# MKW38A4 register map
Vendor: NXP Semiconductors; Series: Kinetis_W; File version: 1.6
CPU: CM0PLUS r0p0, little endian, no MPU, no FPU, VTOR, 2 interrupt priority bits
Registers are 32-bit, read-write, no defined reset value unless marked. A register's access mark holds for its fields unless they carry their own. Offsets are from the block's base; [hi:lo] are bit positions; {n}, {i} and the like mark numbered series.

## NVIC — Nested Vectored Interrupt Controller
Base 0xE000E100
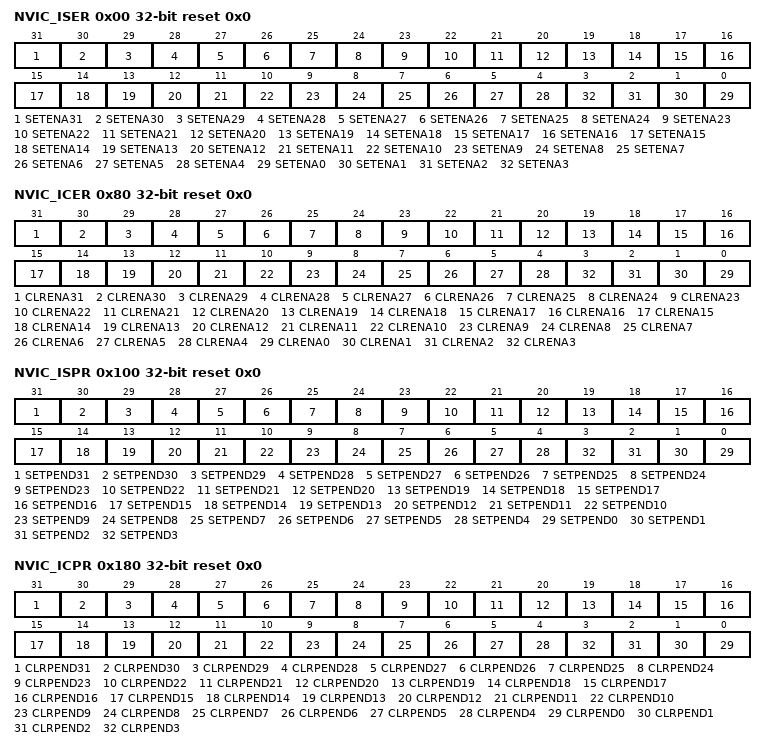
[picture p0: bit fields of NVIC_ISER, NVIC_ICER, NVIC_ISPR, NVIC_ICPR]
0x00 NVIC_ISER reset 0x0 — Interrupt Set Enable Register
  [31] SETENA31 — Pin detect Port B and C interrupt set-enable bit
    0=write: no effect; read: Pin detect Port B and C interrupt disabled; 1=write: enable Pin detect Port B and C interrupt; read: Pin detect Port B and C interrupt enabled
  [30] SETENA30 — Pin detect Port A interrupt set-enable bit
    0=write: no effect; read: Pin detect Port A interrupt disabled; 1=write: enable Pin detect Port A interrupt; read: Pin detect Port A interrupt enabled
  [29] SETENA29 — Serial Peripheral Interface 1 interrupt set-enable bit
    0=write: no effect; read: Serial Peripheral Interface 1 interrupt disabled; 1=write: enable Serial Peripheral Interface 1 interrupt; read: Serial Peripheral Interface 1 interrupt enabled
  [28] SETENA28 — Low-Power Timer 0 interrupt set-enable bit
    0=write: no effect; read: Low-Power Timer 0 interrupt disabled; 1=write: enable Low-Power Timer 0 interrupt; read: Low-Power Timer 0 interrupt enabled
  [27] SETENA27 — Multipurpose Clock Generator interrupt set-enable bit
    0=write: no effect; read: Multipurpose Clock Generator interrupt disabled; 1=write: enable Multipurpose Clock Generator interrupt; read: Multipurpose Clock Generator interrupt enabled
  [26] SETENA26 — Radio 1 interrupt set-enable bit
    0=write: no effect; read: Radio 1 interrupt disabled; 1=write: enable Radio 1 interrupt; read: Radio 1 interrupt enabled
  [25] SETENA25 — FlexCAN0 ORed Message Buffer (MB0-31) interrupt interrupt set-enable bit
    0=write: no effect; read: FlexCAN0 ORed Message Buffer (MB0-31) interrupt interrupt disabled; 1=write: enable FlexCAN0 ORed Message Buffer (MB0-31) interrupt interrupt; read: FlexCAN0 ORed Message Buffer (MB0-31) interrupt interrupt enabled
  [24] SETENA24 — Radio 0 interrupt set-enable bit
    0=write: no effect; read: Radio 0 interrupt disabled; 1=write: enable Radio 0 interrupt; read: Radio 0 interrupt enabled
  [23] SETENA23 — LTC0 interrupt set-enable bit
    0=write: no effect; read: LTC0 interrupt disabled; 1=write: enable LTC0 interrupt; read: LTC0 interrupt enabled
  [22] SETENA22 — Periodic Interrupt Timer interrupt set-enable bit
    0=write: no effect; read: Periodic Interrupt Timer interrupt disabled; 1=write: enable Periodic Interrupt Timer interrupt; read: Periodic Interrupt Timer interrupt enabled
  [21] SETENA21 — RTC seconds interrupt set-enable bit
    0=write: no effect; read: RTC seconds interrupt disabled; 1=write: enable RTC seconds interrupt; read: RTC seconds interrupt enabled
  [20] SETENA20 — Real-time counter interrupt set-enable bit
    0=write: no effect; read: Real-time counter interrupt disabled; 1=write: enable Real-time counter interrupt; read: Real-time counter interrupt enabled
  [19] SETENA19 — Timer/PWM module 2 interrupt set-enable bit
    0=write: no effect; read: Timer/PWM module 2 interrupt disabled; 1=write: enable Timer/PWM module 2 interrupt; read: Timer/PWM module 2 interrupt enabled
  [18] SETENA18 — Timer/PWM module 1 interrupt set-enable bit
    0=write: no effect; read: Timer/PWM module 1 interrupt disabled; 1=write: enable Timer/PWM module 1 interrupt; read: Timer/PWM module 1 interrupt enabled
  [17] SETENA17 — Timer/PWM module 0 interrupt set-enable bit
    0=write: no effect; read: Timer/PWM module 0 interrupt disabled; 1=write: enable Timer/PWM module 0 interrupt; read: Timer/PWM module 0 interrupt enabled
  [16] SETENA16 — DMA channel 0 - 31 error interrupt set-enable bit
    0=write: no effect; read: DMA channel 0 - 31 error interrupt disabled; 1=write: enable DMA channel 0 - 31 error interrupt; read: DMA channel 0 - 31 error interrupt enabled
  [15] SETENA15 — Analog-to-Digital Converter 0 interrupt set-enable bit
    0=write: no effect; read: Analog-to-Digital Converter 0 interrupt disabled; 1=write: enable Analog-to-Digital Converter 0 interrupt; read: Analog-to-Digital Converter 0 interrupt enabled
  [14] SETENA14 — Carrier modulator transmitter interrupt set-enable bit
    0=write: no effect; read: Carrier modulator transmitter interrupt disabled; 1=write: enable Carrier modulator transmitter interrupt; read: Carrier modulator transmitter interrupt enabled
  [13] SETENA13 — True Random Number Generator interrupt set-enable bit
    0=write: no effect; read: True Random Number Generator interrupt disabled; 1=write: enable True Random Number Generator interrupt; read: True Random Number Generator interrupt enabled
  [12] SETENA12 — LPUART0 or LPUART1 status and error interrupt set-enable bit
    0=write: no effect; read: LPUART0 or LPUART1 status and error interrupt disabled; 1=write: enable LPUART0 or LPUART1 status and error interrupt; read: LPUART0 or LPUART1 status and error interrupt enabled
  [11] SETENA11 — FlexCAN0 ORed Error, Bus off, Transmit/Receive Warning, Wake up interrupt set-enable bit
    0=write: no effect; read: FlexCAN0 ORed Error, Bus off, Transmit/Receive Warning, Wake up interrupt disabled; 1=write: enable FlexCAN0 ORed Error, Bus off, Transmit/Receive Warning, Wake up interrupt; read: FlexCAN0 ORed Error, Bus off, Transmit/Receive Warning, Wake up interrupt enabled
  [10] SETENA10 — Serial Peripheral Interface 0 interrupt set-enable bit
    0=write: no effect; read: Serial Peripheral Interface 0 interrupt disabled; 1=write: enable Serial Peripheral Interface 0 interrupt; read: Serial Peripheral Interface 0 interrupt enabled
  [9] SETENA9 — Inter-Integrated Circuit 1 interrupt set-enable bit
    0=write: no effect; read: Inter-Integrated Circuit 1 interrupt disabled; 1=write: enable Inter-Integrated Circuit 1 interrupt; read: Inter-Integrated Circuit 1 interrupt enabled
  [8] SETENA8 — Inter-Integrated Circuit 0 interrupt set-enable bit
    0=write: no effect; read: Inter-Integrated Circuit 0 interrupt disabled; 1=write: enable Inter-Integrated Circuit 0 interrupt; read: Inter-Integrated Circuit 0 interrupt enabled
  [7] SETENA7 — Low Leakage Wakeup interrupt set-enable bit
    0=write: no effect; read: Low Leakage Wakeup interrupt disabled; 1=write: enable Low Leakage Wakeup interrupt; read: Low Leakage Wakeup interrupt enabled
  [6] SETENA6 — Low-voltage detect, low-voltage warning and DCDC PSWITCH interrupt interrupt set-enable bit
    0=write: no effect; read: Low-voltage detect, low-voltage warning and DCDC PSWITCH interrupt interrupt disabled; 1=write: enable Low-voltage detect, low-voltage warning and DCDC PSWITCH interrupt interrupt; read: Low-voltage detect, low-voltage warning and DCDC PSWITCH interrupt interrupt enabled
  [5] SETENA5 — Command complete and read collision, Flash ECC Errors interrupt set-enable bit
    0=write: no effect; read: Command complete and read collision, Flash ECC Errors interrupt disabled; 1=write: enable Command complete and read collision, Flash ECC Errors interrupt; read: Command complete and read collision, Flash ECC Errors interrupt enabled
  [4] SETENA4 — FIFO underrun, FIFO overflow, data ready, transfer complete and error interrupt set-enable bit
    0=write: no effect; read: FIFO underrun, FIFO overflow, data ready, transfer complete and error interrupt disabled; 1=write: enable FIFO underrun, FIFO overflow, data ready, transfer complete and error interrupt; read: FIFO underrun, FIFO overflow, data ready, transfer complete and error interrupt enabled
  [n] SETENA{n} (n=0..3) — DMA channel {n} transfer complete/error interrupt set-enable bit
    0=write: no effect; read: DMA channel {n} transfer complete/error interrupt disabled; 1=write: enable DMA channel {n} transfer complete/error interrupt; read: DMA channel {n} transfer complete/error interrupt enabled
0x80 NVIC_ICER reset 0x0 — Interrupt Clear Enable Register
  [31] CLRENA31 — Pin detect Port B and C interrupt clear-enable bit
    0=write: no effect; read: Pin detect Port B and C interrupt disabled; 1=write: disable Pin detect Port B and C interrupt; read: Pin detect Port B and C interrupt enabled
  [30] CLRENA30 — Pin detect Port A interrupt clear-enable bit
    0=write: no effect; read: Pin detect Port A interrupt disabled; 1=write: disable Pin detect Port A interrupt; read: Pin detect Port A interrupt enabled
  [29] CLRENA29 — Serial Peripheral Interface 1 interrupt clear-enable bit
    0=write: no effect; read: Serial Peripheral Interface 1 interrupt disabled; 1=write: disable Serial Peripheral Interface 1 interrupt; read: Serial Peripheral Interface 1 interrupt enabled
  [28] CLRENA28 — Low-Power Timer 0 interrupt clear-enable bit
    0=write: no effect; read: Low-Power Timer 0 interrupt disabled; 1=write: disable Low-Power Timer 0 interrupt; read: Low-Power Timer 0 interrupt enabled
  [27] CLRENA27 — Multipurpose Clock Generator interrupt clear-enable bit
    0=write: no effect; read: Multipurpose Clock Generator interrupt disabled; 1=write: disable Multipurpose Clock Generator interrupt; read: Multipurpose Clock Generator interrupt enabled
  [26] CLRENA26 — Radio 1 interrupt clear-enable bit
    0=write: no effect; read: Radio 1 interrupt disabled; 1=write: disable Radio 1 interrupt; read: Radio 1 interrupt enabled
  [25] CLRENA25 — FlexCAN0 ORed Message Buffer (MB0-31) interrupt interrupt clear-enable bit
    0=write: no effect; read: FlexCAN0 ORed Message Buffer (MB0-31) interrupt interrupt disabled; 1=write: disable FlexCAN0 ORed Message Buffer (MB0-31) interrupt interrupt; read: FlexCAN0 ORed Message Buffer (MB0-31) interrupt interrupt enabled
  [24] CLRENA24 — Radio 0 interrupt clear-enable bit
    0=write: no effect; read: Radio 0 interrupt disabled; 1=write: disable Radio 0 interrupt; read: Radio 0 interrupt enabled
  [23] CLRENA23 — LTC0 interrupt clear-enable bit
    0=write: no effect; read: LTC0 interrupt disabled; 1=write: disable LTC0 interrupt; read: LTC0 interrupt enabled
  [22] CLRENA22 — Periodic Interrupt Timer interrupt clear-enable bit
    0=write: no effect; read: Periodic Interrupt Timer interrupt disabled; 1=write: disable Periodic Interrupt Timer interrupt; read: Periodic Interrupt Timer interrupt enabled
  [21] CLRENA21 — RTC seconds interrupt clear-enable bit
    0=write: no effect; read: RTC seconds interrupt disabled; 1=write: disable RTC seconds interrupt; read: RTC seconds interrupt enabled
  [20] CLRENA20 — Real-time counter interrupt clear-enable bit
    0=write: no effect; read: Real-time counter interrupt disabled; 1=write: disable Real-time counter interrupt; read: Real-time counter interrupt enabled
  [19] CLRENA19 — Timer/PWM module 2 interrupt clear-enable bit
    0=write: no effect; read: Timer/PWM module 2 interrupt disabled; 1=write: disable Timer/PWM module 2 interrupt; read: Timer/PWM module 2 interrupt enabled
  [18] CLRENA18 — Timer/PWM module 1 interrupt clear-enable bit
    0=write: no effect; read: Timer/PWM module 1 interrupt disabled; 1=write: disable Timer/PWM module 1 interrupt; read: Timer/PWM module 1 interrupt enabled
  [17] CLRENA17 — Timer/PWM module 0 interrupt clear-enable bit
    0=write: no effect; read: Timer/PWM module 0 interrupt disabled; 1=write: disable Timer/PWM module 0 interrupt; read: Timer/PWM module 0 interrupt enabled
  [16] CLRENA16 — DMA channel 0 - 31 error interrupt clear-enable bit
    0=write: no effect; read: DMA channel 0 - 31 error interrupt disabled; 1=write: disable DMA channel 0 - 31 error interrupt; read: DMA channel 0 - 31 error interrupt enabled
  [15] CLRENA15 — Analog-to-Digital Converter 0 interrupt clear-enable bit
    0=write: no effect; read: Analog-to-Digital Converter 0 interrupt disabled; 1=write: disable Analog-to-Digital Converter 0 interrupt; read: Analog-to-Digital Converter 0 interrupt enabled
  [14] CLRENA14 — Carrier modulator transmitter interrupt clear-enable bit
    0=write: no effect; read: Carrier modulator transmitter interrupt disabled; 1=write: disable Carrier modulator transmitter interrupt; read: Carrier modulator transmitter interrupt enabled
  [13] CLRENA13 — True Random Number Generator interrupt clear-enable bit
    0=write: no effect; read: True Random Number Generator interrupt disabled; 1=write: disable True Random Number Generator interrupt; read: True Random Number Generator interrupt enabled
  [12] CLRENA12 — LPUART0 or LPUART1 status and error interrupt clear-enable bit
    0=write: no effect; read: LPUART0 or LPUART1 status and error interrupt disabled; 1=write: disable LPUART0 or LPUART1 status and error interrupt; read: LPUART0 or LPUART1 status and error interrupt enabled
  [11] CLRENA11 — FlexCAN0 ORed Error, Bus off, Transmit/Receive Warning, Wake up interrupt clear-enable bit
    0=write: no effect; read: FlexCAN0 ORed Error, Bus off, Transmit/Receive Warning, Wake up interrupt disabled; 1=write: disable FlexCAN0 ORed Error, Bus off, Transmit/Receive Warning, Wake up interrupt; read: FlexCAN0 ORed Error, Bus off, Transmit/Receive Warning, Wake up interrupt enabled
  [10] CLRENA10 — Serial Peripheral Interface 0 interrupt clear-enable bit
    0=write: no effect; read: Serial Peripheral Interface 0 interrupt disabled; 1=write: disable Serial Peripheral Interface 0 interrupt; read: Serial Peripheral Interface 0 interrupt enabled
  [9] CLRENA9 — Inter-Integrated Circuit 1 interrupt clear-enable bit
    0=write: no effect; read: Inter-Integrated Circuit 1 interrupt disabled; 1=write: disable Inter-Integrated Circuit 1 interrupt; read: Inter-Integrated Circuit 1 interrupt enabled
  [8] CLRENA8 — Inter-Integrated Circuit 0 interrupt clear-enable bit
    0=write: no effect; read: Inter-Integrated Circuit 0 interrupt disabled; 1=write: disable Inter-Integrated Circuit 0 interrupt; read: Inter-Integrated Circuit 0 interrupt enabled
  [7] CLRENA7 — Low Leakage Wakeup interrupt clear-enable bit
    0=write: no effect; read: Low Leakage Wakeup interrupt disabled; 1=write: disable Low Leakage Wakeup interrupt; read: Low Leakage Wakeup interrupt enabled
  [6] CLRENA6 — Low-voltage detect, low-voltage warning and DCDC PSWITCH interrupt interrupt clear-enable bit
    0=write: no effect; read: Low-voltage detect, low-voltage warning and DCDC PSWITCH interrupt interrupt disabled; 1=write: disable Low-voltage detect, low-voltage warning and DCDC PSWITCH interrupt interrupt; read: Low-voltage detect, low-voltage warning and DCDC PSWITCH interrupt interrupt enabled
  [5] CLRENA5 — Command complete and read collision, Flash ECC Errors interrupt clear-enable bit
    0=write: no effect; read: Command complete and read collision, Flash ECC Errors interrupt disabled; 1=write: disable Command complete and read collision, Flash ECC Errors interrupt; read: Command complete and read collision, Flash ECC Errors interrupt enabled
  [4] CLRENA4 — FIFO underrun, FIFO overflow, data ready, transfer complete and error interrupt clear-enable bit
    0=write: no effect; read: FIFO underrun, FIFO overflow, data ready, transfer complete and error interrupt disabled; 1=write: disable FIFO underrun, FIFO overflow, data ready, transfer complete and error interrupt; read: FIFO underrun, FIFO overflow, data ready, transfer complete and error interrupt enabled
  [n] CLRENA{n} (n=0..3) — DMA channel {n} transfer complete/error interrupt clear-enable bit
    0=write: no effect; read: DMA channel {n} transfer complete/error interrupt disabled; 1=write: disable DMA channel {n} transfer complete/error interrupt; read: DMA channel {n} transfer complete/error interrupt enabled
0x100 NVIC_ISPR reset 0x0 — Interrupt Set Pending Register
  [31] SETPEND31 — Pin detect Port B and C interrupt set-pending bit
    0=write: no effect; read: Pin detect Port B and C interrupt is not pending; 1=write: changes the Pin detect Port B and C interrupt state to pending; read: Pin detect Port B and C interrupt is pending
  [30] SETPEND30 — Pin detect Port A interrupt set-pending bit
    0=write: no effect; read: Pin detect Port A interrupt is not pending; 1=write: changes the Pin detect Port A interrupt state to pending; read: Pin detect Port A interrupt is pending
  [29] SETPEND29 — Serial Peripheral Interface 1 interrupt set-pending bit
    0=write: no effect; read: Serial Peripheral Interface 1 interrupt is not pending; 1=write: changes the Serial Peripheral Interface 1 interrupt state to pending; read: Serial Peripheral Interface 1 interrupt is pending
  [28] SETPEND28 — Low-Power Timer 0 interrupt set-pending bit
    0=write: no effect; read: Low-Power Timer 0 interrupt is not pending; 1=write: changes the Low-Power Timer 0 interrupt state to pending; read: Low-Power Timer 0 interrupt is pending
  [27] SETPEND27 — Multipurpose Clock Generator interrupt set-pending bit
    0=write: no effect; read: Multipurpose Clock Generator interrupt is not pending; 1=write: changes the Multipurpose Clock Generator interrupt state to pending; read: Multipurpose Clock Generator interrupt is pending
  [26] SETPEND26 — Radio 1 interrupt set-pending bit
    0=write: no effect; read: Radio 1 interrupt is not pending; 1=write: changes the Radio 1 interrupt state to pending; read: Radio 1 interrupt is pending
  [25] SETPEND25 — FlexCAN0 ORed Message Buffer (MB0-31) interrupt interrupt set-pending bit
    0=write: no effect; read: FlexCAN0 ORed Message Buffer (MB0-31) interrupt interrupt is not pending; 1=write: changes the FlexCAN0 ORed Message Buffer (MB0-31) interrupt interrupt state to pending; read: FlexCAN0 ORed Message Buffer (MB0-31) interrupt interrupt is pending
  [24] SETPEND24 — Radio 0 interrupt set-pending bit
    0=write: no effect; read: Radio 0 interrupt is not pending; 1=write: changes the Radio 0 interrupt state to pending; read: Radio 0 interrupt is pending
  [23] SETPEND23 — LTC0 interrupt set-pending bit
    0=write: no effect; read: LTC0 interrupt is not pending; 1=write: changes the LTC0 interrupt state to pending; read: LTC0 interrupt is pending
  [22] SETPEND22 — Periodic Interrupt Timer interrupt set-pending bit
    0=write: no effect; read: Periodic Interrupt Timer interrupt is not pending; 1=write: changes the Periodic Interrupt Timer interrupt state to pending; read: Periodic Interrupt Timer interrupt is pending
  [21] SETPEND21 — RTC seconds interrupt set-pending bit
    0=write: no effect; read: RTC seconds interrupt is not pending; 1=write: changes the RTC seconds interrupt state to pending; read: RTC seconds interrupt is pending
  [20] SETPEND20 — Real-time counter interrupt set-pending bit
    0=write: no effect; read: Real-time counter interrupt is not pending; 1=write: changes the Real-time counter interrupt state to pending; read: Real-time counter interrupt is pending
  [19] SETPEND19 — Timer/PWM module 2 interrupt set-pending bit
    0=write: no effect; read: Timer/PWM module 2 interrupt is not pending; 1=write: changes the Timer/PWM module 2 interrupt state to pending; read: Timer/PWM module 2 interrupt is pending
  [18] SETPEND18 — Timer/PWM module 1 interrupt set-pending bit
    0=write: no effect; read: Timer/PWM module 1 interrupt is not pending; 1=write: changes the Timer/PWM module 1 interrupt state to pending; read: Timer/PWM module 1 interrupt is pending
  [17] SETPEND17 — Timer/PWM module 0 interrupt set-pending bit
    0=write: no effect; read: Timer/PWM module 0 interrupt is not pending; 1=write: changes the Timer/PWM module 0 interrupt state to pending; read: Timer/PWM module 0 interrupt is pending
  [16] SETPEND16 — DMA channel 0 - 31 error interrupt set-pending bit
    0=write: no effect; read: DMA channel 0 - 31 error interrupt is not pending; 1=write: changes the DMA channel 0 - 31 error interrupt state to pending; read: DMA channel 0 - 31 error interrupt is pending
  [15] SETPEND15 — Analog-to-Digital Converter 0 interrupt set-pending bit
    0=write: no effect; read: Analog-to-Digital Converter 0 interrupt is not pending; 1=write: changes the Analog-to-Digital Converter 0 interrupt state to pending; read: Analog-to-Digital Converter 0 interrupt is pending
  [14] SETPEND14 — Carrier modulator transmitter interrupt set-pending bit
    0=write: no effect; read: Carrier modulator transmitter interrupt is not pending; 1=write: changes the Carrier modulator transmitter interrupt state to pending; read: Carrier modulator transmitter interrupt is pending
  [13] SETPEND13 — True Random Number Generator interrupt set-pending bit
    0=write: no effect; read: True Random Number Generator interrupt is not pending; 1=write: changes the True Random Number Generator interrupt state to pending; read: True Random Number Generator interrupt is pending
  [12] SETPEND12 — LPUART0 or LPUART1 status and error interrupt set-pending bit
    0=write: no effect; read: LPUART0 or LPUART1 status and error interrupt is not pending; 1=write: changes the LPUART0 or LPUART1 status and error interrupt state to pending; read: LPUART0 or LPUART1 status and error interrupt is pending
  [11] SETPEND11 — FlexCAN0 ORed Error, Bus off, Transmit/Receive Warning, Wake up interrupt set-pending bit
    0=write: no effect; read: FlexCAN0 ORed Error, Bus off, Transmit/Receive Warning, Wake up interrupt is not pending; 1=write: changes the FlexCAN0 ORed Error, Bus off, Transmit/Receive Warning, Wake up interrupt state to pending; read: FlexCAN0 ORed Error, Bus off, Transmit/Receive Warning, Wake up interrupt is pending
  [10] SETPEND10 — Serial Peripheral Interface 0 interrupt set-pending bit
    0=write: no effect; read: Serial Peripheral Interface 0 interrupt is not pending; 1=write: changes the Serial Peripheral Interface 0 interrupt state to pending; read: Serial Peripheral Interface 0 interrupt is pending
  [9] SETPEND9 — Inter-Integrated Circuit 1 interrupt set-pending bit
    0=write: no effect; read: Inter-Integrated Circuit 1 interrupt is not pending; 1=write: changes the Inter-Integrated Circuit 1 interrupt state to pending; read: Inter-Integrated Circuit 1 interrupt is pending
  [8] SETPEND8 — Inter-Integrated Circuit 0 interrupt set-pending bit
    0=write: no effect; read: Inter-Integrated Circuit 0 interrupt is not pending; 1=write: changes the Inter-Integrated Circuit 0 interrupt state to pending; read: Inter-Integrated Circuit 0 interrupt is pending
  [7] SETPEND7 — Low Leakage Wakeup interrupt set-pending bit
    0=write: no effect; read: Low Leakage Wakeup interrupt is not pending; 1=write: changes the Low Leakage Wakeup interrupt state to pending; read: Low Leakage Wakeup interrupt is pending
  [6] SETPEND6 — Low-voltage detect, low-voltage warning and DCDC PSWITCH interrupt interrupt set-pending bit
    0=write: no effect; read: Low-voltage detect, low-voltage warning and DCDC PSWITCH interrupt interrupt is not pending; 1=write: changes the Low-voltage detect, low-voltage warning and DCDC PSWITCH interrupt interrupt state to pending; read: Low-voltage detect, low-voltage warning and DCDC PSWITCH interrupt interrupt is pending
  [5] SETPEND5 — Command complete and read collision, Flash ECC Errors interrupt set-pending bit
    0=write: no effect; read: Command complete and read collision, Flash ECC Errors interrupt is not pending; 1=write: changes the Command complete and read collision, Flash ECC Errors interrupt state to pending; read: Command complete and read collision, Flash ECC Errors interrupt is pending
  [4] SETPEND4 — FIFO underrun, FIFO overflow, data ready, transfer complete and error interrupt set-pending bit
    0=write: no effect; read: FIFO underrun, FIFO overflow, data ready, transfer complete and error interrupt is not pending; 1=write: changes the FIFO underrun, FIFO overflow, data ready, transfer complete and error interrupt state to pending; read: FIFO underrun, FIFO overflow, data ready, transfer complete and error interrupt is pending
  [n] SETPEND{n} (n=0..3) — DMA channel {n} transfer complete/error interrupt set-pending bit
    0=write: no effect; read: DMA channel {n} transfer complete/error interrupt is not pending; 1=write: changes the DMA channel {n} transfer complete/error interrupt state to pending; read: DMA channel {n} transfer complete/error interrupt is pending
0x180 NVIC_ICPR reset 0x0 — Interrupt Clear Pending Register
  [31] CLRPEND31 — Pin detect Port B and C interrupt clear-pending bit
    0=write: no effect; read: Pin detect Port B and C interrupt is not pending; 1=write: removes pending state from the Pin detect Port B and C interrupt; read: Pin detect Port B and C interrupt is pending
  [30] CLRPEND30 — Pin detect Port A interrupt clear-pending bit
    0=write: no effect; read: Pin detect Port A interrupt is not pending; 1=write: removes pending state from the Pin detect Port A interrupt; read: Pin detect Port A interrupt is pending
  [29] CLRPEND29 — Serial Peripheral Interface 1 interrupt clear-pending bit
    0=write: no effect; read: Serial Peripheral Interface 1 interrupt is not pending; 1=write: removes pending state from the Serial Peripheral Interface 1 interrupt; read: Serial Peripheral Interface 1 interrupt is pending
  [28] CLRPEND28 — Low-Power Timer 0 interrupt clear-pending bit
    0=write: no effect; read: Low-Power Timer 0 interrupt is not pending; 1=write: removes pending state from the Low-Power Timer 0 interrupt; read: Low-Power Timer 0 interrupt is pending
  [27] CLRPEND27 — Multipurpose Clock Generator interrupt clear-pending bit
    0=write: no effect; read: Multipurpose Clock Generator interrupt is not pending; 1=write: removes pending state from the Multipurpose Clock Generator interrupt; read: Multipurpose Clock Generator interrupt is pending
  [26] CLRPEND26 — Radio 1 interrupt clear-pending bit
    0=write: no effect; read: Radio 1 interrupt is not pending; 1=write: removes pending state from the Radio 1 interrupt; read: Radio 1 interrupt is pending
  [25] CLRPEND25 — FlexCAN0 ORed Message Buffer (MB0-31) interrupt interrupt clear-pending bit
    0=write: no effect; read: FlexCAN0 ORed Message Buffer (MB0-31) interrupt interrupt is not pending; 1=write: removes pending state from the FlexCAN0 ORed Message Buffer (MB0-31) interrupt interrupt; read: FlexCAN0 ORed Message Buffer (MB0-31) interrupt interrupt is pending
  [24] CLRPEND24 — Radio 0 interrupt clear-pending bit
    0=write: no effect; read: Radio 0 interrupt is not pending; 1=write: removes pending state from the Radio 0 interrupt; read: Radio 0 interrupt is pending
  [23] CLRPEND23 — LTC0 interrupt clear-pending bit
    0=write: no effect; read: LTC0 interrupt is not pending; 1=write: removes pending state from the LTC0 interrupt; read: LTC0 interrupt is pending
  [22] CLRPEND22 — Periodic Interrupt Timer interrupt clear-pending bit
    0=write: no effect; read: Periodic Interrupt Timer interrupt is not pending; 1=write: removes pending state from the Periodic Interrupt Timer interrupt; read: Periodic Interrupt Timer interrupt is pending
  [21] CLRPEND21 — RTC seconds interrupt clear-pending bit
    0=write: no effect; read: RTC seconds interrupt is not pending; 1=write: removes pending state from the RTC seconds interrupt; read: RTC seconds interrupt is pending
  [20] CLRPEND20 — Real-time counter interrupt clear-pending bit
    0=write: no effect; read: Real-time counter interrupt is not pending; 1=write: removes pending state from the Real-time counter interrupt; read: Real-time counter interrupt is pending
  [19] CLRPEND19 — Timer/PWM module 2 interrupt clear-pending bit
    0=write: no effect; read: Timer/PWM module 2 interrupt is not pending; 1=write: removes pending state from the Timer/PWM module 2 interrupt; read: Timer/PWM module 2 interrupt is pending
  [18] CLRPEND18 — Timer/PWM module 1 interrupt clear-pending bit
    0=write: no effect; read: Timer/PWM module 1 interrupt is not pending; 1=write: removes pending state from the Timer/PWM module 1 interrupt; read: Timer/PWM module 1 interrupt is pending
  [17] CLRPEND17 — Timer/PWM module 0 interrupt clear-pending bit
    0=write: no effect; read: Timer/PWM module 0 interrupt is not pending; 1=write: removes pending state from the Timer/PWM module 0 interrupt; read: Timer/PWM module 0 interrupt is pending
  [16] CLRPEND16 — DMA channel 0 - 31 error interrupt clear-pending bit
    0=write: no effect; read: DMA channel 0 - 31 error interrupt is not pending; 1=write: removes pending state from the DMA channel 0 - 31 error interrupt; read: DMA channel 0 - 31 error interrupt is pending
  [15] CLRPEND15 — Analog-to-Digital Converter 0 interrupt clear-pending bit
    0=write: no effect; read: Analog-to-Digital Converter 0 interrupt is not pending; 1=write: removes pending state from the Analog-to-Digital Converter 0 interrupt; read: Analog-to-Digital Converter 0 interrupt is pending
  [14] CLRPEND14 — Carrier modulator transmitter interrupt clear-pending bit
    0=write: no effect; read: Carrier modulator transmitter interrupt is not pending; 1=write: removes pending state from the Carrier modulator transmitter interrupt; read: Carrier modulator transmitter interrupt is pending
  [13] CLRPEND13 — True Random Number Generator interrupt clear-pending bit
    0=write: no effect; read: True Random Number Generator interrupt is not pending; 1=write: removes pending state from the True Random Number Generator interrupt; read: True Random Number Generator interrupt is pending
  [12] CLRPEND12 — LPUART0 or LPUART1 status and error interrupt clear-pending bit
    0=write: no effect; read: LPUART0 or LPUART1 status and error interrupt is not pending; 1=write: removes pending state from the LPUART0 or LPUART1 status and error interrupt; read: LPUART0 or LPUART1 status and error interrupt is pending
  [11] CLRPEND11 — FlexCAN0 ORed Error, Bus off, Transmit/Receive Warning, Wake up interrupt clear-pending bit
    0=write: no effect; read: FlexCAN0 ORed Error, Bus off, Transmit/Receive Warning, Wake up interrupt is not pending; 1=write: removes pending state from the FlexCAN0 ORed Error, Bus off, Transmit/Receive Warning, Wake up interrupt; read: FlexCAN0 ORed Error, Bus off, Transmit/Receive Warning, Wake up interrupt is pending
  [10] CLRPEND10 — Serial Peripheral Interface 0 interrupt clear-pending bit
    0=write: no effect; read: Serial Peripheral Interface 0 interrupt is not pending; 1=write: removes pending state from the Serial Peripheral Interface 0 interrupt; read: Serial Peripheral Interface 0 interrupt is pending
  [9] CLRPEND9 — Inter-Integrated Circuit 1 interrupt clear-pending bit
    0=write: no effect; read: Inter-Integrated Circuit 1 interrupt is not pending; 1=write: removes pending state from the Inter-Integrated Circuit 1 interrupt; read: Inter-Integrated Circuit 1 interrupt is pending
  [8] CLRPEND8 — Inter-Integrated Circuit 0 interrupt clear-pending bit
    0=write: no effect; read: Inter-Integrated Circuit 0 interrupt is not pending; 1=write: removes pending state from the Inter-Integrated Circuit 0 interrupt; read: Inter-Integrated Circuit 0 interrupt is pending
  [7] CLRPEND7 — Low Leakage Wakeup interrupt clear-pending bit
    0=write: no effect; read: Low Leakage Wakeup interrupt is not pending; 1=write: removes pending state from the Low Leakage Wakeup interrupt; read: Low Leakage Wakeup interrupt is pending
  [6] CLRPEND6 — Low-voltage detect, low-voltage warning and DCDC PSWITCH interrupt interrupt clear-pending bit
    0=write: no effect; read: Low-voltage detect, low-voltage warning and DCDC PSWITCH interrupt interrupt is not pending; 1=write: removes pending state from the Low-voltage detect, low-voltage warning and DCDC PSWITCH interrupt interrupt; read: Low-voltage detect, low-voltage warning and DCDC PSWITCH interrupt interrupt is pending
  [5] CLRPEND5 — Command complete and read collision, Flash ECC Errors interrupt clear-pending bit
    0=write: no effect; read: Command complete and read collision, Flash ECC Errors interrupt is not pending; 1=write: removes pending state from the Command complete and read collision, Flash ECC Errors interrupt; read: Command complete and read collision, Flash ECC Errors interrupt is pending
  [4] CLRPEND4 — FIFO underrun, FIFO overflow, data ready, transfer complete and error interrupt clear-pending bit
    0=write: no effect; read: FIFO underrun, FIFO overflow, data ready, transfer complete and error interrupt is not pending; 1=write: removes pending state from the FIFO underrun, FIFO overflow, data ready, transfer complete and error interrupt; read: FIFO underrun, FIFO overflow, data ready, transfer complete and error interrupt is pending
  [n] CLRPEND{n} (n=0..3) — DMA channel {n} transfer complete/error interrupt clear-pending bit
    0=write: no effect; read: DMA channel {n} transfer complete/error interrupt is not pending; 1=write: removes pending state from the DMA channel {n} transfer complete/error interrupt; read: DMA channel {n} transfer complete/error interrupt is pending
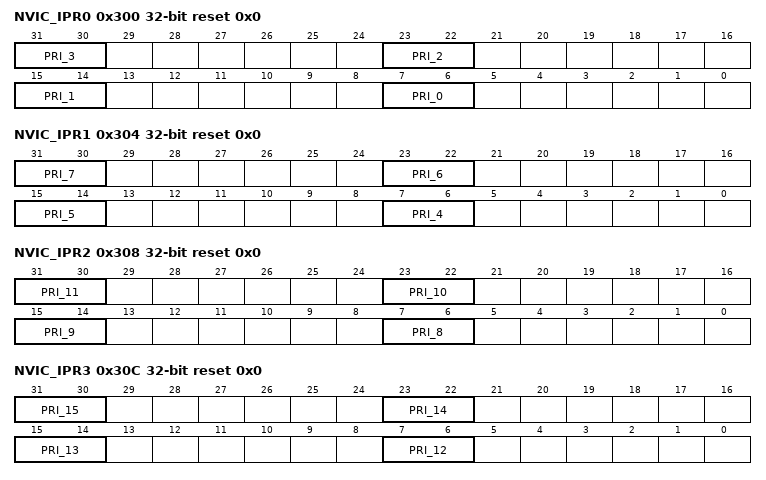
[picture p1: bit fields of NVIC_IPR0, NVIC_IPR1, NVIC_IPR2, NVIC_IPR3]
0x300 NVIC_IPR0 reset 0x0 — Interrupt Priority Register 0
  [8n+7:8n+6] PRI_{n} (n=0..3) — Priority of the DMA channel {n} transfer complete/error interrupt
0x304 NVIC_IPR1 reset 0x0 — Interrupt Priority Register 1
  [31:30] PRI_7 — Priority of the Low Leakage Wakeup interrupt
  [23:22] PRI_6 — Priority of the Low-voltage detect, low-voltage warning and DCDC PSWITCH interrupt interrupt
  [15:14] PRI_5 — Priority of the Command complete and read collision, Flash ECC Errors interrupt
  [7:6] PRI_4 — Priority of the FIFO underrun, FIFO overflow, data ready, transfer complete and error interrupt
0x308 NVIC_IPR2 reset 0x0 — Interrupt Priority Register 2
  [31:30] PRI_11 — Priority of the FlexCAN0 ORed Error, Bus off, Transmit/Receive Warning, Wake up interrupt
  [23:22] PRI_10 — Priority of the Serial Peripheral Interface 0 interrupt
  [15:14] PRI_9 — Priority of the Inter-Integrated Circuit 1 interrupt
  [7:6] PRI_8 — Priority of the Inter-Integrated Circuit 0 interrupt
0x30C NVIC_IPR3 reset 0x0 — Interrupt Priority Register 3
  [31:30] PRI_15 — Priority of the Analog-to-Digital Converter 0 interrupt
  [23:22] PRI_14 — Priority of the Carrier modulator transmitter interrupt
  [15:14] PRI_13 — Priority of the True Random Number Generator interrupt
  [7:6] PRI_12 — Priority of the LPUART0 or LPUART1 status and error interrupt
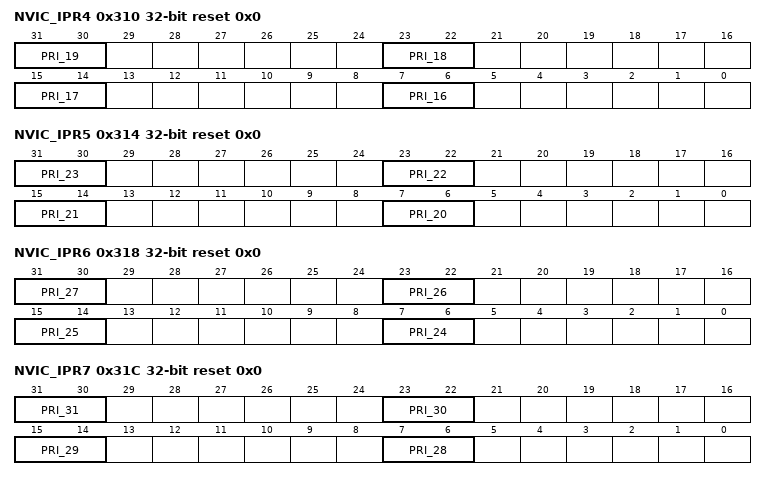
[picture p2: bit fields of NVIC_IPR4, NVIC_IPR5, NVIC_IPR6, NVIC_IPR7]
0x310 NVIC_IPR4 reset 0x0 — Interrupt Priority Register 4
  [31:30] PRI_19 — Priority of the Timer/PWM module 2 interrupt
  [23:22] PRI_18 — Priority of the Timer/PWM module 1 interrupt
  [15:14] PRI_17 — Priority of the Timer/PWM module 0 interrupt
  [7:6] PRI_16 — Priority of the DMA channel 0 - 31 error interrupt
0x314 NVIC_IPR5 reset 0x0 — Interrupt Priority Register 5
  [31:30] PRI_23 — Priority of the LTC0 interrupt
  [23:22] PRI_22 — Priority of the Periodic Interrupt Timer interrupt
  [15:14] PRI_21 — Priority of the RTC seconds interrupt
  [7:6] PRI_20 — Priority of the Real-time counter interrupt
0x318 NVIC_IPR6 reset 0x0 — Interrupt Priority Register 6
  [31:30] PRI_27 — Priority of the Multipurpose Clock Generator interrupt
  [23:22] PRI_26 — Priority of the Radio 1 interrupt
  [15:14] PRI_25 — Priority of the FlexCAN0 ORed Message Buffer (MB0-31) interrupt interrupt
  [7:6] PRI_24 — Priority of the Radio 0 interrupt
0x31C NVIC_IPR7 reset 0x0 — Interrupt Priority Register 7
  [31:30] PRI_31 — Priority of the Pin detect Port B and C interrupt
  [23:22] PRI_30 — Priority of the Pin detect Port A interrupt
  [15:14] PRI_29 — Priority of the Serial Peripheral Interface 1 interrupt
  [7:6] PRI_28 — Priority of the Low-Power Timer 0 interrupt
